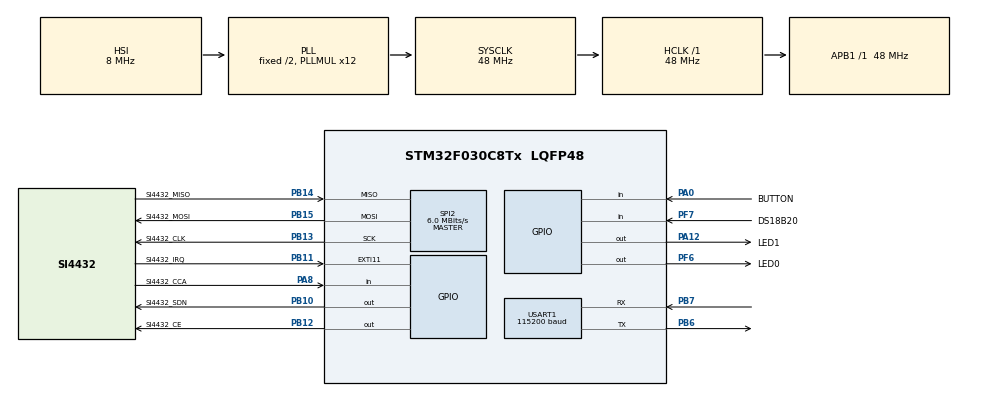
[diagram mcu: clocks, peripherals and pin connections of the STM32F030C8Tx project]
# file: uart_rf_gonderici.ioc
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Dma.Request0=USART1_RX
Dma.Request1=USART1_TX
Dma.USART1_RX.0.Direction=DMA_PERIPH_TO_MEMORY
Dma.USART1_RX.0.Instance=DMA1_Channel3
Dma.USART1_RX.0.MemDataAlignment=DMA_MDATAALIGN_BYTE
Dma.USART1_RX.0.MemInc=DMA_MINC_ENABLE
Dma.USART1_RX.0.Mode=DMA_CIRCULAR
Dma.USART1_RX.0.PeriphDataAlignment=DMA_PDATAALIGN_BYTE
Dma.USART1_RX.0.PeriphInc=DMA_PINC_DISABLE
Dma.USART1_RX.0.Priority=DMA_PRIORITY_LOW
Dma.USART1_TX.1.Direction=DMA_MEMORY_TO_PERIPH
Dma.USART1_TX.1.Instance=DMA1_Channel2
Dma.USART1_TX.1.MemDataAlignment=DMA_MDATAALIGN_BYTE
Dma.USART1_TX.1.MemInc=DMA_MINC_ENABLE
Dma.USART1_TX.1.Mode=DMA_NORMAL
Dma.USART1_TX.1.PeriphDataAlignment=DMA_PDATAALIGN_BYTE
Dma.USART1_TX.1.PeriphInc=DMA_PINC_DISABLE
Dma.USART1_TX.1.Priority=DMA_PRIORITY_LOW
IWDG.Prescaler=IWDG_PRESCALER_256
Mcu.Family=STM32F0
Mcu.Name=STM32F030C8Tx
Mcu.Package=LQFP48
NVIC.DMA1_Channel2_3_IRQn=true\:3\:0\:true\:false\:true\:true\:true\:true
NVIC.EXTI4_15_IRQn=true\:1\:0\:true\:false\:true\:true\:true\:true
NVIC.TIM17_IRQn=true\:2\:0\:true\:false\:true\:true\:true\:true
NVIC.USART1_IRQn=true\:3\:0\:true\:false\:true\:true\:true\:true
PA0.GPIO_Label=BUTTON
PA0.Signal=GPIO_Input
PA12.GPIO_Label=LED1
PA12.Signal=GPIO_Output
PA13.Mode=Serial_Wire
PA13.Signal=SYS_SWDIO
PA14.Mode=Serial_Wire
PA14.Signal=SYS_SWCLK
PA2.Signal=USART2_TX
PA3.Signal=USART2_RX
PA8.GPIO_Label=SI4432_CCA
PA8.Signal=GPIO_Input
PB10.GPIO_Label=SI4432_SDN
PB10.PinState=GPIO_PIN_SET
PB10.Signal=GPIO_Output
PB11.GPIO_Label=SI4432_IRQ
PB11.GPIO_ModeDefaultEXTI=GPIO_MODE_IT_RISING_FALLING
PB11.GPIO_PuPd=GPIO_PULLUP
PB11.Signal=GPXTI11
PB12.GPIO_Label=SI4432_CE
PB12.Signal=GPIO_Output
PB13.GPIO_Label=SI4432_CLK
PB13.Mode=Full_Duplex_Master
PB13.Signal=SPI2_SCK
PB14.GPIO_Label=SI4432_MISO
PB14.Mode=Full_Duplex_Master
PB14.Signal=SPI2_MISO
PB15.GPIO_Label=SI4432_MOSI
PB15.Mode=Full_Duplex_Master
PB15.Signal=SPI2_MOSI
PB6.GPIO_PuPd=GPIO_PULLUP
PB6.Mode=Asynchronous
PB6.Signal=USART1_TX
PB7.GPIO_PuPd=GPIO_PULLUP
PB7.Mode=Asynchronous
PB7.Signal=USART1_RX
PF6.GPIO_Label=LED0
PF6.Signal=GPIO_Output
PF7.GPIO_Label=DS18B20
PF7.GPIO_PuPd=GPIO_PULLUP
PF7.Signal=GPIO_Input
ProjectManager.HeapSize=0x500
ProjectManager.StackSize=0x300
ProjectManager.TargetToolchain=STM32CubeIDE
RCC.AHBFreq_Value=48000000
RCC.APB1Freq_Value=48000000
RCC.APB1TimFreq_Value=48000000
RCC.HCLKFreq_Value=48000000
RCC.PLLMUL=RCC_PLL_MUL12
RCC.SYSCLKFreq_VALUE=48000000
RCC.SYSCLKSource=RCC_SYSCLKSOURCE_PLLCLK
SPI2.BaudRatePrescaler=SPI_BAUDRATEPRESCALER_8
SPI2.CalculateBaudRate=6.0 MBits/s
SPI2.DataSize=SPI_DATASIZE_8BIT
SPI2.Direction=SPI_DIRECTION_2LINES
SPI2.Mode=SPI_MODE_MASTER
SPI2.NSSPMode=SPI_NSS_PULSE_DISABLE
SPI2.VirtualType=VM_MASTER
TIM16.Prescaler=47
TIM17.Period=999
TIM17.Prescaler=47
USART1.BaudRate=115200
USART1.DMADisableonRxErrorParam=ADVFEATURE_DMA_DISABLEONRXERROR
USART1.VirtualMode-Asynchronous=VM_ASYNC
VP_IWDG_VS_IWDG.Mode=IWDG_Activate
VP_TIM16_VS_ClockSourceINT.Mode=Enable_Timer
VP_TIM17_VS_ClockSourceINT.Mode=Enable_Timer
board=INO-Server

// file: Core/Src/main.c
/* USER CODE BEGIN Header */
/**
 ******************************************************************************
 * @file           : main.c
 * @brief          : UART→RF Gönderici — Firmware Update Bridge + Test Modu
 ******************************************************************************
 * STM32F030C8 (64KB Flash, 8KB RAM)
 *
 * İki çalışma modu:
 *   1. Normal Mod: UART'tan metin al → RF'den gönder → Echo bekle (test)
 *   2. Firmware Update Modu: PC'den 'W' gelince aktif
 *      PC ←UART→ Gönderici ←RF→ Alıcı Bootloader
 *
 * Firmware Update Akışı:
 *   PC→'W' → RF BOOT_REQUEST → Alıcıdan BOOT_ACK bekle → PC'ye ACK
 *   PC→metadata(12) → RF CMD_METADATA → ACK → PC'ye ACK
 *   Alıcı flash siler → RF FLASH_ERASE_DONE → PC'ye ACK
 *   PC→paket(148) → 3×RF DATA_CHUNK → ACK×3 → PC'ye ACK
 *   ... tekrar ...
 *   Alıcı final → RF UPDATE_COMPLETE/FAILED → PC'ye ACK/NACK
 ******************************************************************************
 */
/* USER CODE END Header */
#include "main.h"
#include "dma.h"
#include "gpio.h"
#include "iwdg.h"
#include "spi.h"
#include "sender_fw_update.h"
#include "sender_normal_mode.h"
#include "sender_state.h"
#include "sender_uart_debug.h"
#include "tim.h"
#include "usart.h"

/* USER CODE BEGIN Includes */
#include "rf_protocol.h"
#include "si4432.h"
/* USER CODE END Includes */

/* USER CODE BEGIN PV */
extern UART_HandleTypeDef huart1;
extern IWDG_HandleTypeDef hiwdg;

/* USER CODE END PV */

void SystemClock_Config(void);

int main(void) {
  /* HAL ve sistem saatini baslat */
  HAL_Init();
  SystemClock_Config(); // HSI x12 PLL = 48 MHz

  /* Cevresel birim (peripheral) baslatma */
  MX_GPIO_Init();       // LED, Si4432 CS/SDN/IRQ pinleri
  MX_DMA_Init();        // DMA kanallari (UART DMA icin)
  MX_USART1_UART_Init(); // 115200 8N1 — PC ile haberlesme
  MX_SPI2_Init();       // Si4432 RF modulu SPI baglantisi
  MX_IWDG_Init();       // Watchdog — kilitlenmeye karsi koruma
  MX_TIM17_Init();      // Timer (kullanilmiyor — ileride rezerve)
  MX_TIM16_Init();      // Timer (kullanilmiyor — ileride rezerve)

  /* Si4432 RF modul baslatma */
  SI4432_Init();
  HAL_Delay(10);

  /* Device Type Register (0x00) kontrol — 0x08 olmali
   * Bu deger Si4432 icin Silicon Labs'in belirtigi deger.
   * Diger deger: baglanti sorunu veya yanlis cihaz. */
  uint8_t dev = SI4432_ReadReg(0x00);
  if (dev != 0x08) {
    SendDiag(DIAG_LEVEL_ERROR, DIAG_ERR_SI4432_INIT, "Si4432 bulunamadi - SPI/kablo kontrol edin");
    /* Si4432 bulunamadi — LED hizli yanip sonsun, sonsuz dongu */
    while (1) {
      HAL_GPIO_TogglePin(LED0_GPIO_Port, LED0_Pin);
      HAL_Delay(100);
      HAL_IWDG_Refresh(&hiwdg);
    }
  }

  /* Basarili baslama gostergesi: her iki LED 1 sn yansın */
  HAL_GPIO_WritePin(LED0_GPIO_Port, LED0_Pin, GPIO_PIN_SET);
  HAL_GPIO_WritePin(LED1_GPIO_Port, LED1_Pin, GPIO_PIN_SET);
  HAL_Delay(1000);
  HAL_GPIO_WritePin(LED0_GPIO_Port, LED0_Pin, GPIO_PIN_RESET);
  HAL_GPIO_WritePin(LED1_GPIO_Port, LED1_Pin, GPIO_PIN_RESET);

  /* Terminal karsilama mesaji */
  Print("\r\n========================================\r\n");
  Print(" Si4432 RF Gonderici + FW Update Bridge\r\n");
  Print("========================================\r\n");
  Print("DEV_TYPE: ");
  PrintHex(dev); // 0x08 olmali
  Print("\r\nMesaj yaz + Enter (normal mod)\r\n");
  Print("'W' gondererek FW update modu baslatilir\r\n\r\n");
  SendDiag(DIAG_LEVEL_INFO, DIAG_INFO_READY, "Si4432 OK - Gonderici hazir");

  /* Ana dongu */
  while (1) {
    HAL_IWDG_Refresh(&hiwdg); // Watchdog'u her donguде sifirla

    /* 50 ms bekleme ile bir UART karakteri al.
     * Timeout ile dongu bloke olmaz — watchdog calismaya devam eder. */
    uint8_t ch;
    if (HAL_UART_Receive(&huart1, &ch, 1, 50) == HAL_OK) {
      HandleNormalModeByte(ch); // sender_normal_mode.c — karakteri isle
      /* NOT: 'W' gelirse HandleNormalModeByte icinden FirmwareUpdate_Mode()
       * cagrılır; o fonksiyon donene kadar bu satir bekler. */
    }
  }
}

/*
 * SystemClock_Config — Sistem saatini yapilandir
 *
 * HSI (8 MHz dahili osilatör) → PLL x12 → SYSCLK = 48 MHz
 * HCLK = SYSCLK = 48 MHz, APB1 = HCLK / 1 = 48 MHz
 * LSI: IWDG icin kullanilir
 */
void SystemClock_Config(void) {
  RCC_OscInitTypeDef RCC_OscInitStruct = {0};
  RCC_ClkInitTypeDef RCC_ClkInitStruct = {0};

  RCC_OscInitStruct.OscillatorType =
      RCC_OSCILLATORTYPE_HSI | RCC_OSCILLATORTYPE_LSI;
  RCC_OscInitStruct.HSIState = RCC_HSI_ON;
  RCC_OscInitStruct.HSICalibrationValue = RCC_HSICALIBRATION_DEFAULT;
  RCC_OscInitStruct.LSIState = RCC_LSI_ON;
  RCC_OscInitStruct.PLL.PLLState = RCC_PLL_ON;
  RCC_OscInitStruct.PLL.PLLSource = RCC_PLLSOURCE_HSI;
  RCC_OscInitStruct.PLL.PLLMUL = RCC_PLL_MUL12;
  RCC_OscInitStruct.PLL.PREDIV = RCC_PREDIV_DIV1;
  if (HAL_RCC_OscConfig(&RCC_OscInitStruct) != HAL_OK)
    Error_Handler();

  RCC_ClkInitStruct.ClockType =
      RCC_CLOCKTYPE_HCLK | RCC_CLOCKTYPE_SYSCLK | RCC_CLOCKTYPE_PCLK1;
  RCC_ClkInitStruct.SYSCLKSource = RCC_SYSCLKSOURCE_PLLCLK;
  RCC_ClkInitStruct.AHBCLKDivider = RCC_SYSCLK_DIV1;
  RCC_ClkInitStruct.APB1CLKDivider = RCC_HCLK_DIV1;
  if (HAL_RCC_ClockConfig(&RCC_ClkInitStruct, FLASH_LATENCY_1) != HAL_OK)
    Error_Handler();
}

void Error_Handler(void) {
  __disable_irq();
  while (1) {
  }
}
